VERSION ""

NS_ :

BS_: 500

BU_: Vector__XXX

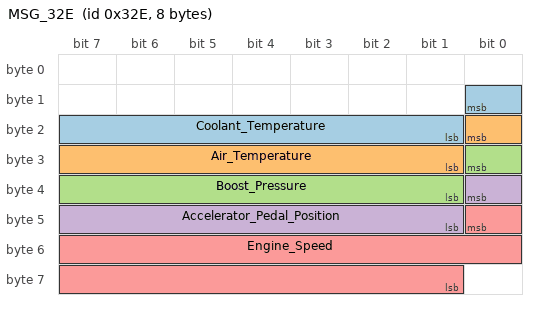
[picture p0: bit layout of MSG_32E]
BO_ 814 MSG_32E: 8 Vector__XXX
 SG_ Coolant_Temperature : 8|8@0+ (1,0) [0|255] "��F" Vector__XXX
 SG_ Air_Temperature : 16|8@0+ (1,0) [0|255] "��F" Vector__XXX
 SG_ Boost_Pressure : 24|8@0+ (0.0101523,-1.02487) [-1.02487309645|1.56395939086] "bar" Vector__XXX
 SG_ Accelerator_Pedal_Position : 32|8@0+ (0.561798,-33.7079) [-33.7078651685|109.550561798] "%" Vector__XXX
 SG_ Engine_Speed : 40|16@0+ (1,0) [0|10000] "rpm" Vector__XXX
